# CTRL_MMR0_CTRL_MMR0_IPC_MMRS_09080000h register map
Vendor: Texas Instruments
Peripheral module from a debugger description file (folder am62L).
Registers are 32-bit, access not given, reset 0x0 unless marked. A register's access mark holds for its fields unless they carry their own. Offsets are as the file gives them; lines under a group give offsets from that group; [hi:lo] are bit positions; {n}, {i} and the like mark numbered series; 'fields as' and 'values as' point back to an identical list; <NAME> marks a mode.

## CTRL_MMR0_IPC_MMRS
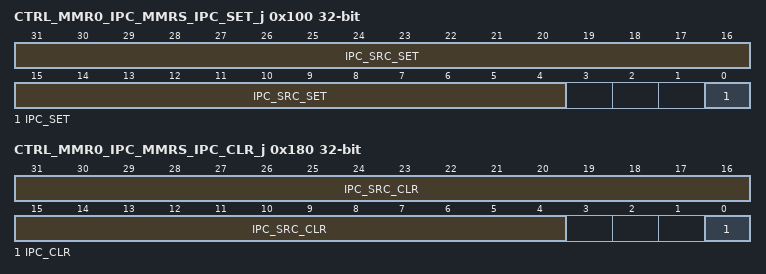
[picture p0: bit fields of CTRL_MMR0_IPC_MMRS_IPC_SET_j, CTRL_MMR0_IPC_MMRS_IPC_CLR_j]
0x100 CTRL_MMR0_IPC_MMRS_IPC_SET_j — Generate interprocessor communication interrupt
  [31:4] IPC_SRC_SET — Read returns current valueWrite: 0 - No effect 1 - Sets both corresponding IPC_CLR and the IPC_SET bits Reset Source: mod_g_rst_n (access R/W1TS)
  [0] IPC_SET — Read returns 0Write: 0 - No effect 1 - Sets both corresponding IPC_CLR and the IPC_SET bits Reset Source: mod_g_rst_n (access R/W1TS)
0x180 CTRL_MMR0_IPC_MMRS_IPC_CLR_j — Acknowledge interprocessor communication interrupt
  [31:4] IPC_SRC_CLR — Read returns current valueWrite: 0 - No effect 1 - Clears both corresponding IPC_CLR and the IPC_SET bits Reset Source: mod_g_rst_n (access R/W1TC)
  [0] IPC_CLR — Read returns current valueWrite: 0 - No effect 1 - Clears both corresponding IPC_CLR and the IPC_SET bits Reset Source: mod_g_rst_n (access R/W1TC)
